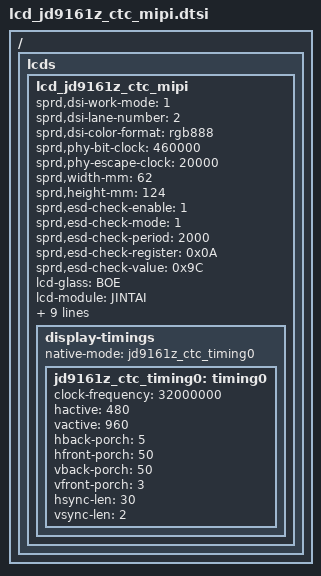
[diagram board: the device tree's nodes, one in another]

/*
 * JD9161Z King LCD config dtsi file for spreadtrum
 *
 * Copyright (C) 2019, Spreadtrum Communications Inc.
 *
 * SPDX-License-Identifier: (GPL-2.0+ OR MIT)
 */

/ {
	fragment {
		target-path = "/";
		__overlay__ {
			lcds {
				lcd_jd9161z_ctc_mipi: lcd_jd9161z_ctc_mipi {

					sprd,dsi-work-mode = <1>; /* video burst mode*/
					sprd,dsi-lane-number = <2>;
					sprd,dsi-color-format = "rgb888";

					sprd,phy-bit-clock = <460000>;	/* kbps */
					sprd,phy-escape-clock = <20000>;/* kHz */

					sprd,width-mm = <62>;
					sprd,height-mm = <124>;

					sprd,esd-check-enable = <1>;
					sprd,esd-check-mode = <1>;
					sprd,esd-check-period = <2000>;
					sprd,esd-check-register = <0x0A>;
					sprd,esd-check-value = <0x9C>;

					lcd-glass = "BOE";
					lcd-module = "JINTAI";
					lcd-name = "JD9161Z";

					sprd,reset-on-sequence = <1 10>, <0 10>, <1 100>;
					sprd,reset-off-sequence = <1 20>;

					//sprd,use-dcs-write;
					sprd,initial-command = [
						39 00 00 04 DF 91 62 F3
						39 00 00 07 B7 10 26 58 00 78 28
						39 00 00 0C BB 65 1B 32 32 32 C0 E0 30 F0 50 50
						39 00 00 02 C0 22
						39 00 00 0F C3 74 03 07 0E 00 0E 0E 0E 0E 00 0E	92 07 92
						39 00 00 14 C8 7E 74 65 54 4C 3B 40 29 46 48 4C 6F 64 74 6D 73 6C 62 08
						39 00 00 13 7E 74 65 54 4C 3B 40 29 46 48 4C 6F 64 74 6D 73 6C 62 08
						39 00 00 11 D0 51 5F 41 5E 5F 4B 45 47 49 5F 5F 5F 5F 5F 5F 5F
						39 00 00 11 D1 50 5F 40 5E 5F 4A 44 46 48 5F 5F 5F 5F 5F 5F 5F
						39 00 00 11 D2 00 1F 10 1F 1E 04 0A 08 06 1F 1F 1F 1F 1F 1F 1F
						39 00 00 11 D3 01 1F 11 1F 1E 05 0B 09 07 1F 1F 1F 1F 1F 1F 1F
						39 00 00 1E D4 10 00 00 03 60 06 10 00 02 0C 7C 08 74 CC 13 A0 00 0C 7C 71 0A 0A 6A 04 25 00 63 03 00
						39 00 00 29 D5 10 3F 08 20 00 00 00 18 00 00 06 60 00 07 50 01 33 D8 00 60 C0 00 00 00 03 60 03 10 00 00 0F 4F 00 10 1F 3F 00 00 00 00

						23 00 00 02 DE 02
									
						23 00 00 02 C1 11
						23 00 00 02 BE 0F
						23 00 00 02 DE 00

						23 32 00 02 35 00

						23 78 00 01 11
						39 0A 00 01 29
						];
					sprd,sleep-in-command = [
						23 0A 00 01 28
						23 78 00 01 10
						];
					sprd,sleep-out-command = [

						23 78 00 01 11
						23 0A 00 01 29
						];

					display-timings {
						native-mode = <&jd9161z_ctc_timing0>;

						jd9161z_ctc_timing0:timing0 {
							clock-frequency = <32000000>;
							hactive = <480>;
							vactive = <960>;
							hback-porch = <5>;
							hfront-porch = <50>;
							vback-porch = <50>;
							vfront-porch = <3>;
							hsync-len = <30>;
							vsync-len = <2>;
						};
					};
				};
			};
		};
	};
};
